AUTOSAR XML (schema 4.0)
package /Powertrain
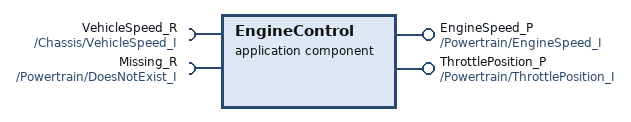
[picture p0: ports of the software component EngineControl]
  application sw component type EngineControl
    provide port EngineSpeed_P: provided-interface=/Powertrain/EngineSpeed_I
    provide port ThrottlePosition_P: provided-interface=/Powertrain/ThrottlePosition_I
    require port VehicleSpeed_R: required-interface=/Chassis/VehicleSpeed_I
    require port Missing_R: required-interface=/Powertrain/DoesNotExist_I
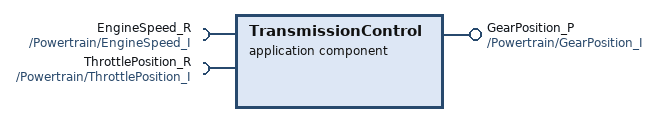
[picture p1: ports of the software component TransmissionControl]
  application sw component type TransmissionControl
    require port EngineSpeed_R: required-interface=/Powertrain/EngineSpeed_I
    require port ThrottlePosition_R: required-interface=/Powertrain/ThrottlePosition_I
    provide port GearPosition_P: provided-interface=/Powertrain/GearPosition_I
